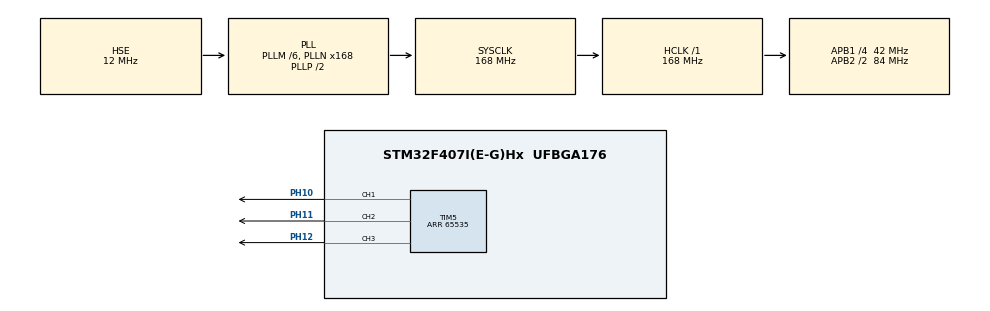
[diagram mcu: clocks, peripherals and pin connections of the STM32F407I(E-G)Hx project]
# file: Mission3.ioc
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FREERTOS.Tasks01=defaultTask,0,128,StartDefaultTask,Default,NULL,Dynamic,NULL,NULL;led_b,0,128,led_b_task,Default,NULL,Dynamic,NULL,NULL;led_g,0,128,led_g_task,Default,NULL,Dynamic,NULL,NULL;led_r,0,128,led_r_task,Default,NULL,Dynamic,NULL,NULL
Mcu.Family=STM32F4
Mcu.Name=STM32F407I(E-G)Hx
Mcu.Package=UFBGA176
NVIC.PriorityGroup=NVIC_PRIORITYGROUP_4
PA13.Mode=Serial_Wire
PA13.Signal=SYS_JTMS-SWDIO
PA14.Mode=Serial_Wire
PA14.Signal=SYS_JTCK-SWCLK
PH0-OSC_IN.Mode=HSE-External-Oscillator
PH0-OSC_IN.Signal=RCC_OSC_IN
PH1-OSC_OUT.Mode=HSE-External-Oscillator
PH1-OSC_OUT.Signal=RCC_OSC_OUT
PH10.Signal=S_TIM5_CH1
PH11.Signal=S_TIM5_CH2
PH12.Signal=S_TIM5_CH3
ProjectManager.HeapSize=0x200
ProjectManager.StackSize=0x400
ProjectManager.TargetToolchain=MDK-ARM V5.32
RCC.48MHZClocksFreq_Value=84000000
RCC.AHBFreq_Value=168000000
RCC.APB1CLKDivider=RCC_HCLK_DIV4
RCC.APB1Freq_Value=42000000
RCC.APB1TimFreq_Value=84000000
RCC.APB2CLKDivider=RCC_HCLK_DIV2
RCC.APB2Freq_Value=84000000
RCC.APB2TimFreq_Value=168000000
RCC.CortexFreq_Value=168000000
RCC.HCLKFreq_Value=168000000
RCC.HSE_VALUE=12000000
RCC.HSI_VALUE=16000000
RCC.LSE_VALUE=32768
RCC.PLLM=6
RCC.PLLN=168
RCC.PLLSourceVirtual=RCC_PLLSOURCE_HSE
RCC.SYSCLKFreq_VALUE=168000000
RCC.SYSCLKSource=RCC_SYSCLKSOURCE_PLLCLK
RCC.VCOOutputFreq_Value=336000000
SH.S_TIM5_CH1.0=TIM5_CH1,PWM Generation1 CH1
SH.S_TIM5_CH2.0=TIM5_CH2,PWM Generation2 CH2
SH.S_TIM5_CH3.0=TIM5_CH3,PWM Generation3 CH3
TIM5.Channel-PWM\ Generation1\ CH1=TIM_CHANNEL_1
TIM5.Channel-PWM\ Generation2\ CH2=TIM_CHANNEL_2
TIM5.Channel-PWM\ Generation3\ CH3=TIM_CHANNEL_3
TIM5.Period=65535
TIM5.Pulse-PWM\ Generation1\ CH1=10000
TIM5.Pulse-PWM\ Generation2\ CH2=10000
TIM5.Pulse-PWM\ Generation3\ CH3=10000
VP_FREERTOS_VS_CMSIS_V1.Mode=CMSIS_V1
VP_TIM5_VS_ClockSourceINT.Mode=Internal
board=custom

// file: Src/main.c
/* USER CODE BEGIN Header */
/**
  ******************************************************************************
  * @file           : main.c
  * @brief          : Main program body
  ******************************************************************************
  * @attention
  *
  * Copyright (c) 2022 STMicroelectronics.
  * All rights reserved.
  *
  * This software is licensed under terms that can be found in the LICENSE file
  * in the root directory of this software component.
  * If no LICENSE file comes with this software, it is provided AS-IS.
  *
  ******************************************************************************
  */
/* USER CODE END Header */
#include "main.h"
#include "cmsis_os.h"
#include "tim.h"
#include "gpio.h"

/* USER CODE BEGIN PV */
uint32_t aRGB = 0xAA00AA00;
/* USER CODE END PV */

void SystemClock_Config(void);
void MX_FREERTOS_Init(void);

int main(void)
{

  /* MCU Configuration--------------------------------------------------------*/

  /* Reset of all peripherals, Initializes the Flash interface and the Systick. */
  HAL_Init();

  /* Configure the system clock */
  SystemClock_Config();

  /* Initialize all configured peripherals */
  MX_GPIO_Init();
  MX_TIM5_Init();
  /* USER CODE BEGIN 2 */
  HAL_TIM_PWM_Start(&htim5,TIM_CHANNEL_1);
  HAL_TIM_PWM_Start(&htim5,TIM_CHANNEL_2);
  HAL_TIM_PWM_Start(&htim5,TIM_CHANNEL_3);
  /* USER CODE END 2 */

  /* Call init function for freertos objects (in freertos.c) */
  MX_FREERTOS_Init();

  /* Start scheduler */
  osKernelStart();

  /* We should never get here as control is now taken by the scheduler */
  /* Infinite loop */
  while (1)
  {

  }
}

void SystemClock_Config(void)
{
  RCC_OscInitTypeDef RCC_OscInitStruct = {0};
  RCC_ClkInitTypeDef RCC_ClkInitStruct = {0};

  /** Configure the main internal regulator output voltage
  */
  __HAL_RCC_PWR_CLK_ENABLE();
  __HAL_PWR_VOLTAGESCALING_CONFIG(PWR_REGULATOR_VOLTAGE_SCALE1);

  /** Initializes the RCC Oscillators according to the specified parameters
  * in the RCC_OscInitTypeDef structure.
  */
  RCC_OscInitStruct.OscillatorType = RCC_OSCILLATORTYPE_HSE;
  RCC_OscInitStruct.HSEState = RCC_HSE_ON;
  RCC_OscInitStruct.PLL.PLLState = RCC_PLL_ON;
  RCC_OscInitStruct.PLL.PLLSource = RCC_PLLSOURCE_HSE;
  RCC_OscInitStruct.PLL.PLLM = 6;
  RCC_OscInitStruct.PLL.PLLN = 168;
  RCC_OscInitStruct.PLL.PLLP = RCC_PLLP_DIV2;
  RCC_OscInitStruct.PLL.PLLQ = 4;
  if (HAL_RCC_OscConfig(&RCC_OscInitStruct) != HAL_OK)
  {
    Error_Handler();
  }

  /** Initializes the CPU, AHB and APB buses clocks
  */
  RCC_ClkInitStruct.ClockType = RCC_CLOCKTYPE_HCLK|RCC_CLOCKTYPE_SYSCLK
                              |RCC_CLOCKTYPE_PCLK1|RCC_CLOCKTYPE_PCLK2;
  RCC_ClkInitStruct.SYSCLKSource = RCC_SYSCLKSOURCE_PLLCLK;
  RCC_ClkInitStruct.AHBCLKDivider = RCC_SYSCLK_DIV1;
  RCC_ClkInitStruct.APB1CLKDivider = RCC_HCLK_DIV4;
  RCC_ClkInitStruct.APB2CLKDivider = RCC_HCLK_DIV2;

  if (HAL_RCC_ClockConfig(&RCC_ClkInitStruct, FLASH_LATENCY_5) != HAL_OK)
  {
    Error_Handler();
  }
}

void Error_Handler(void)
{
  __disable_irq();
  while (1)
  {
  }
}

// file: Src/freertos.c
/* USER CODE BEGIN Header */
/**
  ******************************************************************************
  * File Name          : freertos.c
  * Description        : Code for freertos applications
  ******************************************************************************
  * @attention
  *
  * Copyright (c) 2022 STMicroelectronics.
  * All rights reserved.
  *
  * This software is licensed under terms that can be found in the LICENSE file
  * in the root directory of this software component.
  * If no LICENSE file comes with this software, it is provided AS-IS.
  *
  ******************************************************************************
  */
/* USER CODE END Header */

#include "FreeRTOS.h"
#include "task.h"
#include "main.h"
#include "cmsis_os.h"

/* USER CODE BEGIN Variables */
extern TIM_HandleTypeDef htim5;
extern uint32_t aRGB;
/* USER CODE END Variables */
//osThreadId defaultTaskHandle;
osThreadId led_bHandle;
osThreadId led_gHandle;
osThreadId led_rHandle;

//void StartDefaultTask(void const * argument);
void led_b_task(void const * argument);
void led_g_task(void const * argument);
void led_r_task(void const * argument);

void MX_FREERTOS_Init(void); /* (MISRA C 2004 rule 8.1) */

/* GetIdleTaskMemory prototype (linked to static allocation support) */
void vApplicationGetIdleTaskMemory( StaticTask_t **ppxIdleTaskTCBBuffer, StackType_t **ppxIdleTaskStackBuffer, uint32_t *pulIdleTaskStackSize );

/* USER CODE BEGIN GET_IDLE_TASK_MEMORY */
static StaticTask_t xIdleTaskTCBBuffer;
static StackType_t xIdleStack[configMINIMAL_STACK_SIZE];

void vApplicationGetIdleTaskMemory( StaticTask_t **ppxIdleTaskTCBBuffer, StackType_t **ppxIdleTaskStackBuffer, uint32_t *pulIdleTaskStackSize )
{
  *ppxIdleTaskTCBBuffer = &xIdleTaskTCBBuffer;
  *ppxIdleTaskStackBuffer = &xIdleStack[0];
  *pulIdleTaskStackSize = configMINIMAL_STACK_SIZE;
  /* place for user code */
}
/* USER CODE END GET_IDLE_TASK_MEMORY */

void MX_FREERTOS_Init(void) {

  /* Create the thread(s) */
  /* definition and creation of defaultTask */
  //osThreadDef(defaultTask, StartDefaultTask, osPriorityNormal, 0, 128);
  //defaultTaskHandle = osThreadCreate(osThread(defaultTask), NULL);

  /* definition and creation of led_b */
  osThreadDef(led_b, led_b_task, osPriorityNormal, 0, 128);
  led_bHandle = osThreadCreate(osThread(led_b), NULL);

  /* definition and creation of led_g */
  osThreadDef(led_g, led_g_task, osPriorityNormal, 0, 128);
  led_gHandle = osThreadCreate(osThread(led_g), NULL);

  /* definition and creation of led_r */
  osThreadDef(led_r, led_r_task, osPriorityNormal, 0, 128);
  led_rHandle = osThreadCreate(osThread(led_r), NULL);

}

/* USER CODE BEGIN Header_StartDefaultTask */
/* USER CODE END Header_led_b_task */
void led_b_task(void const * argument)
{
  /* USER CODE BEGIN led_b_task */
  /* Infinite loop */
  static uint8_t alpha;
  static uint16_t blue;
  while(1)
  {
    alpha =(aRGB & 0xFF000000) >> 24;
    blue = ((aRGB & 0x000000FF) >> 0) * alpha;
    __HAL_TIM_SetCompare(&htim5,TIM_CHANNEL_1,blue);
    osDelay(3000);
    __HAL_TIM_SetCompare(&htim5,TIM_CHANNEL_1,0);
    osDelay(3000);
  }
  /* USER CODE END led_b_task */
}

void led_g_task(void const * argument)
{
  /* USER CODE BEGIN led_g_task */
  /* Infinite loop */
  static uint8_t alpha;
  static uint16_t green;
  while(1)
  {
    alpha =(aRGB & 0xFF000000) >> 24;
    green = ((aRGB & 0x0000FF00) >> 8) * alpha;
    __HAL_TIM_SetCompare(&htim5,TIM_CHANNEL_2,green);
    osDelay(3000);
    __HAL_TIM_SetCompare(&htim5,TIM_CHANNEL_2,0);
    osDelay(3000);
  }
  /* USER CODE END led_g_task */
}

void led_r_task(void const * argument)
{
  /* USER CODE BEGIN led_r_task */
  /* Infinite loop */
  static uint8_t alpha;
  static uint16_t red;
  while(1)
  {
    alpha =(aRGB & 0xFF000000) >> 24;
    red = ((aRGB & 0x00FF0000) >> 16) * alpha;
    __HAL_TIM_SetCompare(&htim5,TIM_CHANNEL_3,red);
    osDelay(3000);
    __HAL_TIM_SetCompare(&htim5,TIM_CHANNEL_3,0);
    osDelay(3000);
  }
  /* USER CODE END led_r_task */
}
